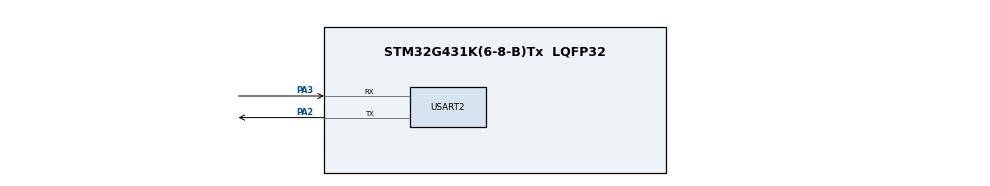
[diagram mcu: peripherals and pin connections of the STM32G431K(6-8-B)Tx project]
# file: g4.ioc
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Mcu.Family=STM32G4
Mcu.Name=STM32G431K(6-8-B)Tx
Mcu.Package=LQFP32
NVIC.PriorityGroup=NVIC_PRIORITYGROUP_4
PA13.Mode=Trace_Asynchronous_SW
PA13.Signal=SYS_JTMS-SWDIO
PA14.Mode=Trace_Asynchronous_SW
PA14.Signal=SYS_JTCK-SWCLK
PA2.Mode=Asynchronous
PA2.Signal=USART2_TX
PA3.Mode=Asynchronous
PA3.Signal=USART2_RX
PB3.Mode=Trace_Asynchronous_SW
PB3.Signal=SYS_JTDO-SWO
ProjectManager.HeapSize=0x200
ProjectManager.StackSize=0x400
ProjectManager.TargetToolchain=Makefile
RCC.ADC12Freq_Value=170000000
RCC.AHBFreq_Value=170000000
RCC.APB1Freq_Value=170000000
RCC.APB1TimFreq_Value=170000000
RCC.APB2Freq_Value=170000000
RCC.APB2TimFreq_Value=170000000
RCC.CortexFreq_Value=170000000
RCC.EXTERNAL_CLOCK_VALUE=12288000
RCC.HCLKFreq_Value=170000000
RCC.HSE_VALUE=8000000
RCC.HSI48_VALUE=48000000
RCC.HSI_VALUE=16000000
RCC.LSE_VALUE=32768
RCC.PLLM=RCC_PLLM_DIV4
RCC.PLLN=85
RCC.SYSCLKFreq_VALUE=170000000
RCC.SYSCLKSource=RCC_SYSCLKSOURCE_PLLCLK
RCC.USBFreq_Value=170000000
RCC.VCOOutputFreq_Value=340000000
USART2.VirtualMode-Asynchronous=VM_ASYNC
VP_SYS_VS_DBSignals.Mode=DisableDeadBatterySignals
board=custom

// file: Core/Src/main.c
/* USER CODE BEGIN Header */
/**
  ******************************************************************************
  * @file           : main.c
  * @brief          : Main program body
  ******************************************************************************
  * @attention
  *
  * <h2><center>&copy; Copyright (c) 2021 STMicroelectronics.
  * All rights reserved.</center></h2>
  *
  * This software component is licensed by ST under BSD 3-Clause license,
  * the "License"; You may not use this file except in compliance with the
  * License. You may obtain a copy of the License at:
  *                        opensource.org/licenses/BSD-3-Clause
  *
  ******************************************************************************
  */
/* USER CODE END Header */
#include "main.h"
#include "usart.h"
#include "gpio.h"

void SystemClock_Config(void);

int main(void)
{

  /* MCU Configuration--------------------------------------------------------*/

  /* Reset of all peripherals, Initializes the Flash interface and the Systick. */

  LL_APB2_GRP1_EnableClock(LL_APB2_GRP1_PERIPH_SYSCFG);
  LL_APB1_GRP1_EnableClock(LL_APB1_GRP1_PERIPH_PWR);

  NVIC_SetPriorityGrouping(NVIC_PRIORITYGROUP_4);

  /* System interrupt init*/
  /* SysTick_IRQn interrupt configuration */
  NVIC_SetPriority(SysTick_IRQn, NVIC_EncodePriority(NVIC_GetPriorityGrouping(),15, 0));

  /** Disable the internal Pull-Up in Dead Battery pins of UCPD peripheral
  */
  LL_PWR_DisableUCPDDeadBattery();

  /* Configure the system clock */
  SystemClock_Config();

  /* Initialize all configured peripherals */
  MX_GPIO_Init();
  MX_USART2_UART_Init();
  /* USER CODE BEGIN 2 */
  extern void mcuboot_main(void);
  mcuboot_main();
  /* USER CODE END 2 */

  /* Infinite loop */
  while (1)
  {

  }
}

void SystemClock_Config(void)
{
  LL_FLASH_SetLatency(LL_FLASH_LATENCY_4);
  while(LL_FLASH_GetLatency() != LL_FLASH_LATENCY_4)
  {
  }
  LL_PWR_EnableRange1BoostMode();
  LL_RCC_HSI_Enable();
   /* Wait till HSI is ready */
  while(LL_RCC_HSI_IsReady() != 1)
  {
  }

  LL_RCC_HSI_SetCalibTrimming(64);
  LL_RCC_PLL_ConfigDomain_SYS(LL_RCC_PLLSOURCE_HSI, LL_RCC_PLLM_DIV_4, 85, LL_RCC_PLLR_DIV_2);
  LL_RCC_PLL_EnableDomain_SYS();
  LL_RCC_PLL_Enable();
   /* Wait till PLL is ready */
  while(LL_RCC_PLL_IsReady() != 1)
  {
  }

  LL_RCC_SetSysClkSource(LL_RCC_SYS_CLKSOURCE_PLL);
  LL_RCC_SetAHBPrescaler(LL_RCC_SYSCLK_DIV_2);
   /* Wait till System clock is ready */
  while(LL_RCC_GetSysClkSource() != LL_RCC_SYS_CLKSOURCE_STATUS_PLL)
  {
  }

  /* Insure 1�s transition state at intermediate medium speed clock based on DWT */
  CoreDebug->DEMCR |= CoreDebug_DEMCR_TRCENA_Msk;
  DWT->CTRL |= DWT_CTRL_CYCCNTENA_Msk;
  DWT->CYCCNT = 0;
  while(DWT->CYCCNT < 100);
  /* Set AHB prescaler*/
  LL_RCC_SetAHBPrescaler(LL_RCC_SYSCLK_DIV_1);
  LL_RCC_SetAPB1Prescaler(LL_RCC_APB1_DIV_1);
  LL_RCC_SetAPB2Prescaler(LL_RCC_APB2_DIV_1);

  LL_Init1msTick(170000000);

  LL_SetSystemCoreClock(170000000);
  LL_RCC_SetUSARTClockSource(LL_RCC_USART2_CLKSOURCE_PCLK1);
}

void Error_Handler(void)
{
  __disable_irq();
  while (1)
  {
  }
}

/************************ (C) COPYRIGHT STMicroelectronics *****END OF FILE****/
